# PIC32CM5164JH01100 register map
Vendor: Microchip Technology; Series: PIC32CMJH01; File version: 0
CPU: CM0+ r0p0, little endian, MPU, no FPU, VTOR, 2 interrupt priority bits, 32 interrupts
Registers are 32-bit, read-write, reset 0x0 unless marked. A register's access mark holds for its fields unless they carry their own. Offsets are from the block's base; [hi:lo] are bit positions; {n}, {i} and the like mark numbered series.

## SMBIST — SRAM MBIST Interface
Base 0x42006C00
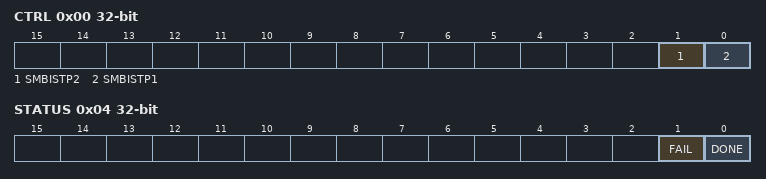
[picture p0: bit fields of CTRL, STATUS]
0x00 CTRL — Control
  [1] SMBISTP2 — SRAM MBIST Partition 2 test start
  [0] SMBISTP1 — SRAM MBIST Partition 1 test start
0x04 STATUS
  [1] FAIL, [0] DONE

## MCLK — Main Clock
Base 0x40000800
0x01 INTENCLR 8-bit write-1-clears — Interrupt Enable Clear
  [0] CKRDY — Clock Ready Interrupt Enable
0x02 INTENSET 8-bit write-1-sets — Interrupt Enable Set
  [0] CKRDY — Clock Ready Interrupt Enable
0x03 INTFLAG 8-bit reset 0x1 write-1-clears — Interrupt Flag Status and Clear
  [0] CKRDY — Clock Ready
0x04 CPUDIV 8-bit reset 0x1 — CPU Clock Division
  [7:0] CPUDIV — CPU Clock Division Factor
    1=DIV1 (Divide by 1); 2=DIV2 (Divide by 2); 4=DIV4 (Divide by 4); 8=DIV8 (Divide by 8); 16=DIV16 (Divide by 16); 32=DIV32 (Divide by 32); 64=DIV64 (Divide by 64); 128=DIV128 (Divide by 128)
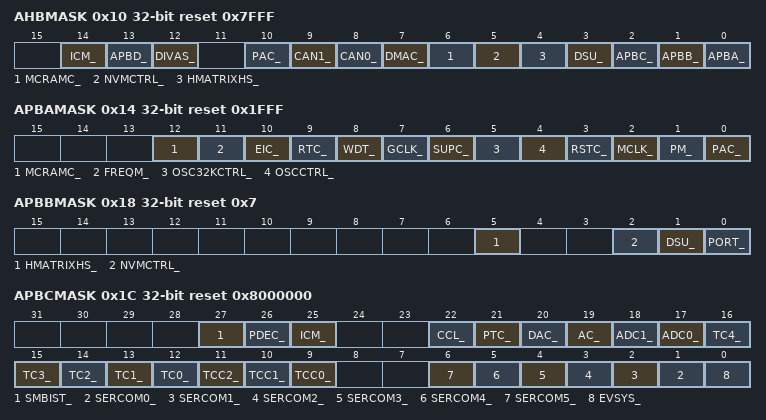
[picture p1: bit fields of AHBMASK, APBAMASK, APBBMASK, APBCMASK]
0x10 AHBMASK reset 0x7FFF
  [14] ICM_ — ICM AHB Clock Mask
  [13] APBD_ — APBD AHB Clock Mask
  [12] DIVAS_ — DIVAS AHB Clock Mask
  [10] PAC_ — PAC AHB Clock Mask
  [9] CAN1_ — CAN1 AHB Clock Mask
  [8] CAN0_ — CAN0 AHB Clock Mask
  [7] DMAC_ — DMAC AHB Clock Mask
  [6] MCRAMC_ — MCRAMC AHB Clock Mask
  [5] NVMCTRL_ — NVMCTRL AHB Clock Mask
  [4] HMATRIXHS_ — HMATRIXHS AHB Clock Mask
  [3] DSU_ — DSU AHB Clock Mask
  [2] APBC_ — APBC AHB Clock Mask
  [1] APBB_ — APBB AHB Clock Mask
  [0] APBA_ — APBA AHB Clock Mask
0x14 APBAMASK reset 0x1FFF
  [12] MCRAMC_ — MCRAMC APB Clock Enable
  [11] FREQM_ — FREQM APB Clock Enable
  [10] EIC_ — EIC APB Clock Enable
  [9] RTC_ — RTC APB Clock Enable
  [8] WDT_ — WDT APB Clock Enable
  [7] GCLK_ — GCLK APB Clock Enable
  [6] SUPC_ — SUPC APB Clock Enable
  [5] OSC32KCTRL_ — OSC32KCTRL APB Clock Enable
  [4] OSCCTRL_ — OSCCTRL APB Clock Enable
  [3] RSTC_ — RSTC APB Clock Enable
  [2] MCLK_ — MCLK APB Clock Enable
  [1] PM_ — PM APB Clock Enable
  [0] PAC_ — PAC APB Clock Enable
0x18 APBBMASK reset 0x7
  [5] HMATRIXHS_ — HMATRIXHS APB Clock Enable
  [2] NVMCTRL_ — NVMCTRL APB Clock Enable
  [1] DSU_ — DSU APB Clock Enable
  [0] PORT_ — PORT APB Clock Enable
0x1C APBCMASK reset 0x8000000
  [27] SMBIST_ — SMBIST APB Clock Enable
  [26] PDEC_ — PDEC APB Clock Enable
  [25] ICM_ — ICM APB Clock Enable
  [22] CCL_ — CCL APB Clock Enable
  [21] PTC_ — PTC APB Clock Enable
  [20] DAC_ — DAC APB Clock Enable
  [19] AC_ — AC APB Clock Enable
  [18] ADC1_ — ADC1 APB Clock Enable
  [17] ADC0_ — ADC0 APB Clock Enable
  [n+12] TC{n}_ (n=0..4) — TC{n} APB Clock Enable
  [11] TCC2_ — TCC2 APB Clock Enable
  [10] TCC1_ — TCC1 APB Clock Enable
  [9] TCC0_ — TCC0 APB Clock Enable
  [n+1] SERCOM{n}_ (n=0..5) — SERCOM{n} APB Clock Enable
  [0] EVSYS_ — EVSYS APB Clock Enable
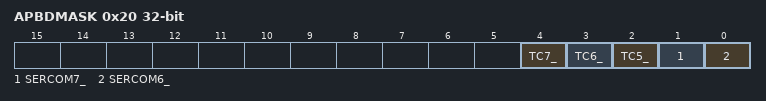
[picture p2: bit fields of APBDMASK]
0x20 APBDMASK
  [4] TC7_ — TC7 APB Clock Enable
  [3] TC6_ — TC6 APB Clock Enable
  [2] TC5_ — TC5 APB Clock Enable
  [1] SERCOM7_ — SERCOM7 APB Clock Enable
  [0] SERCOM6_ — SERCOM6 APB Clock Enable

## MCRAMC — Multi-Channel RAM Controller
Base 0x40003000
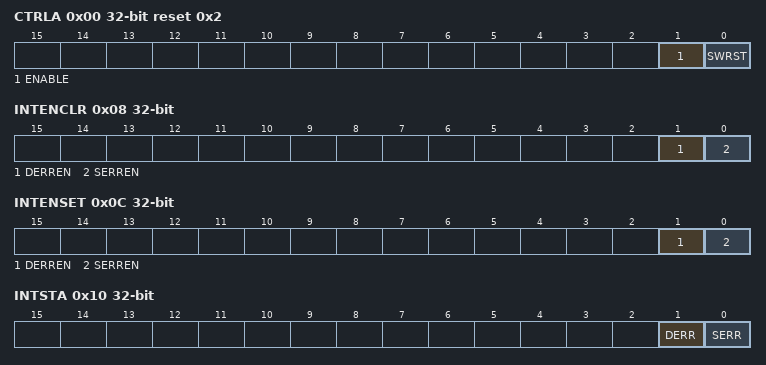
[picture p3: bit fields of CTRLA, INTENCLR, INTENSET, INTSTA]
0x00 CTRLA reset 0x2 — Control Enable A Register
  [1] ENABLE — ECC Decoder Enable
    0=ECC decoding is disabled; 1=ECC decoding is enabled
  [0] SWRST — Software Reset
    0=No effect; 1=Reset the MCRAMC. A software-triggered hardware reset of the MCRAMC user interface is performed.
0x08 INTENCLR write-1-clears — Interrupt Enable Clear Register
  [1] DERREN — Double Bit Error Interrupt Enable, Clear
  [0] SERREN — Single Bit Error Interrupt Enable, Clear
0x0C INTENSET write-1-sets — Interrupt Enable Set Register
  [1] DERREN — Double Bit Error Interrupt Enable, Set
  [0] SERREN — Single Bit Error Interrupt Enable, Set
0x10 INTSTA write-1-clears — Interrupt Status Register
  [1] DERR — Double Bit Error
  [0] SERR — Single Bit Error
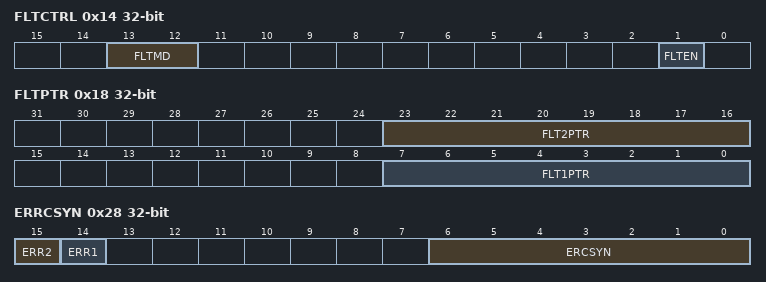
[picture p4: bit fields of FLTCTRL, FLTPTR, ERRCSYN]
0x14 FLTCTRL — Fault Injection Control Register
  [13:12] FLTMD — Fault Injection Mode
    0=DISABLE (Fault Injection Disabled); 1=SINGLE (Single Fault Injection at bit selected by FLTPTR.FTL1PTR); 2=DOUBLE (Double Fault Injection at bits FLTPTR.FTL1PTR and FLTPTR.FTL2PTR)
  [1] FLTEN — Fault Injection Enabled
    0=Disables fault injection; 1=Enables fault injection at FLTADR address offset as selected by FLTMD and FLTxPTR
0x18 FLTPTR — Fault Injection Pointer Register
  [23:16] FLT2PTR — Double Fault Injection Bit Pointer
  [7:0] FLT1PTR — Single Fault Injection Bit Pointer
0x1C FLTADR — Fault Injection Address Register
  [23:0] FLTADR — Fault Address Offset
0x20 ERRCADR ro — Error Capture Address Register
  [23:0] ERCADR — ECC SECDED Error Capture Address
0x24 ERRCPAR ro — Error Capture Parity Register
  [6:0] ERCPAR — ECC SECDED Error Capture Parity
0x28 ERRCSYN ro — Error Capture Syndrome Register
  [15] ERR2 — ECC Double Bit Error
    0=Not a Double bit error; 1=Double bit error
  [14] ERR1 — ECC Single Bit Error
  [6:0] ERCSYN — ECC SECDED Error Capture Syndrome
    0=Not a Single bit error; 1=Single bit error

## Notices in the file
Copyright (c) 2026 Microchip Technology Inc.
SPDX-License-Identifier: Apache-2.0
Licensed under the Apache License, Version 2.0 (the "License");
you may not use this file except in compliance with the License.
You may obtain a copy of the License at
http://www.apache.org/licenses/LICENSE-2.0
Unless required by applicable law or agreed to in writing, software
distributed under the License is distributed on an "AS IS" BASIS,
WITHOUT WARRANTIES OR CONDITIONS OF ANY KIND, either express or implied.
See the License for the specific language governing permissions and
limitations under the License.
